AUTOSAR XML (schema 00044)
package /ComponentTypes
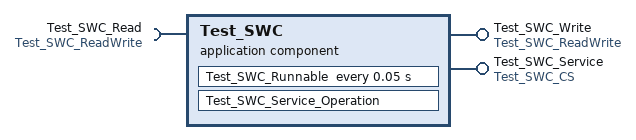
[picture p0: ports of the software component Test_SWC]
  application sw component type Test_SWC
    require port Test_SWC_Read: nonqueued-receiver-com-spec{data-element=Element, init-value=0}, required-interface=Test_SWC_ReadWrite
    provide port Test_SWC_Write: nonqueued-sender-com-spec{data-element=Element, init-value=0}, provided-interface=Test_SWC_ReadWrite
    provide port Test_SWC_Service: server-com-spec{operation=Operation, queue-length=1}, provided-interface=Test_SWC_CS
    behavior Test_SWC_InternalBehavior
      timing event TMT_Test_SWC_Runnable: start-on-event=Test_SWC_Runnable, period=0.05
      operation invoked event OIT_Test_SWC_Service_Operation_Test_SWC_Service_Operation: start-on-event=Test_SWC_Service_Operation, operation=Test_SWC_Service.Operation
      runnable Test_SWC_Runnable: minimum-start-interval=0.05
        data-receive-point-by-arguments:
          access REC_Test_SWC_Read_Element: accessed-variable=Test_SWC_Read.Element
        data-send-points:
          access SEND_Test_SWC_ReadWrite_Element: accessed-variable=Test_SWC_Write.Element
      runnable Test_SWC_Service_Operation
  swc implementation Test_SWC_Implementation: behavior=Test_SWC_InternalBehavior
